# MB9AF31xK register map
Vendor: Cypress; File version: 2.1
CPU: CM3 r2p1, little endian, MPU, no FPU, 4 interrupt priority bits
Registers are 32-bit, read-write, reset 0x0 unless marked. A register's access mark holds for its fields unless they carry their own. Offsets are from the block's base; [hi:lo] are bit positions; 'fields as' and 'values as' point back to an identical list.

## MFS0 — Multi-function Serial Interface 0
Base 0x40038000
Same registers: MFS1 0x40038100
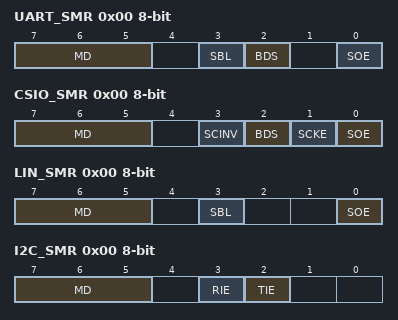
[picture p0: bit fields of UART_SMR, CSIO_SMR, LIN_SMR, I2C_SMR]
0x00 UART_SMR 8-bit (UART view) — Serial Mode Register [BHW]
  [7:5] MD — Operation mode set bit
  [3] SBL — Stop bit length select bit
  [2] BDS — Transfer direction select bit
  [0] SOE — Serial data output enable bit
0x00 CSIO_SMR 8-bit (CSIO view) — Serial Mode Register [BHW]
  [7:5] MD — Operation mode set bits
  [3] SCINV — Serial clock invert bit
  [2] BDS — Transfer direction select bit
  [1] SCKE — Master mode serial clock output enable bit
  [0] SOE — Serial data output enable bit
0x00 LIN_SMR 8-bit (LIN view) — Serial Mode Register [BHW]
  [7:5] MD — Operation mode setting bits
  [3] SBL — Stop bit length select bit
  [0] SOE — Serial data output enable bit
0x00 I2C_SMR 8-bit (I2C view) — Serial Mode Register [BHW]
  [7:5] MD — operation mode set bits
  [3] RIE — Received interrupt enable bit
  [2] TIE — Transmit interrupt enable bit
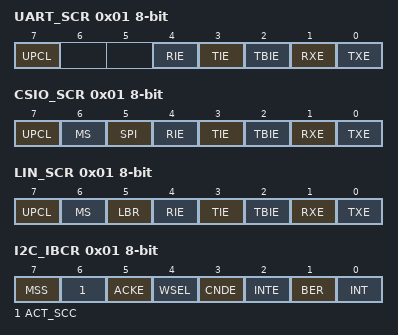
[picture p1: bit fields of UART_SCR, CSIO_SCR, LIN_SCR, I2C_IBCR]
0x01 UART_SCR 8-bit (UART view) — Serial Control Register [BHW]
  [7] UPCL — Programmable Clear bit
  [4] RIE — Received interrupt enable bit
  [3] TIE — Transmit interrupt enable bit
  [2] TBIE — Transmit bus idle interrupt enable bit
  [1] RXE — Received operation enable bit
  [0] TXE — Transmission operation enable bit
0x01 CSIO_SCR 8-bit (CSIO view) — Serial Control Register [BHW]
  [7] UPCL — Programmable clear bit
  [6] MS — Master/Slave function select bit
  [5] SPI — SPI corresponding bit
  [4] RIE — Received interrupt enable bit
  [3] TIE — Transmit interrupt enable bit
  [2] TBIE — Transmit bus idle interrupt enable bit
  [1] RXE — Data received enable bit
  [0] TXE — Data transmission enable bit
0x01 LIN_SCR 8-bit (LIN view) — Serial Control Register [BHW]
  [7] UPCL — Programmable clear bit
  [6] MS — Master/Slave function select bit
  [5] LBR — LIN Break Field setting bit (valid in master mode only)
  [4] RIE — Received interrupt enable bit
  [3] TIE — Transmit interrupt enable bit
  [2] TBIE — Transmit bus idle interrupt enable bit
  [1] RXE — Data reception enable bit
  [0] TXE — Data transmission enable bit
0x01 I2C_IBCR 8-bit (I2C view) — I2C Bus Control Register [BHW]
  [7] MSS — Master/slave select bit
  [6] ACT_SCC — Operation flag/iteration start condition generation bit
  [5] ACKE — Data byte acknowledge enable bit
  [4] WSEL — Wait selection bit
  [3] CNDE — Condition detection interrupt enable bit
  [2] INTE — Interrupt enable bit
  [1] BER ro — Bus error flag bit
  [0] INT — interrupt flag bit
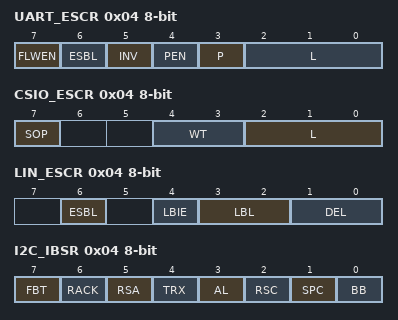
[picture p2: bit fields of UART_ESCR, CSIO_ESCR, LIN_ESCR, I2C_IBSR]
0x04 UART_ESCR 8-bit (UART view) — Extended Communication Control Register [BHW]
  [7] FLWEN — Flow control enable bit
  [6] ESBL — Extension stop bit length select bit
  [5] INV — Inverted serial data format bit
  [4] PEN — Parity enable bit (only functions in operation mode 0)
  [3] P — Parity select bit (only functions in operation mode 0)
  [2:0] L — Data length select bit
0x04 CSIO_ESCR 8-bit (CSIO view) — Extended Communication Control Register [BHW]
  [7] SOP — Serial output pin set bit
  [4:3] WT — Data transmit/received wait select bits
  [2:0] L — Data length select bits
0x04 LIN_ESCR 8-bit (LIN view) — Extended Communication Control Register [BHW]
  [6] ESBL — Extended stop bit length select bit
  [4] LBIE — LIN Break field detect interrupt enable bit
  [3:2] LBL — LIN Break field length select bits (valid in master mode only)
  [1:0] DEL — LIN Break delimiter length select bits (valid in master mode only)
0x04 I2C_IBSR 8-bit (I2C view) — I2C Bus Status Register [BHW]
  [7] FBT ro — First byte bit
  [6] RACK ro — Acknowledge flag bit
  [5] RSA ro — Reserved address detection bit
  [4] TRX ro — Data direction bit
  [3] AL ro — Arbitration lost bit
  [2] RSC — Iteration start condition check bit
  [1] SPC — Stop condition check bit
  [0] BB ro — Bus state bit
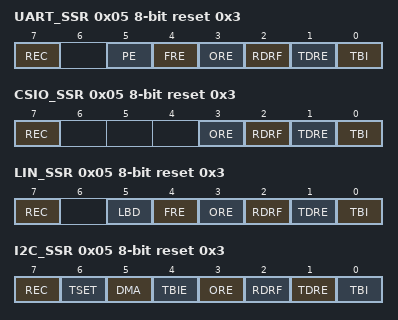
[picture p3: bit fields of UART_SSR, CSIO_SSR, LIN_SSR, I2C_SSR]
0x05 UART_SSR 8-bit reset 0x3 (UART view) — Serial Status Register [BHW]
  [7] REC — Received error flag clear bit
  [5] PE ro — Parity error flag bit (only functions in operation mode 0)
  [4] FRE ro — Framing error flag bit
  [3] ORE ro — Overrun error flag bit
  [2] RDRF ro — Received data full flag bit
  [1] TDRE ro — Transmit data empty flag bit
  [0] TBI ro — Transmit bus idle flag
0x05 CSIO_SSR 8-bit reset 0x3 (CSIO view) — Serial Status Register [BHW]
  [7] REC — Received error flag clear bit
  [3] ORE ro — Overrun error flag bit
  [2] RDRF ro — Received data full flag bit
  [1] TDRE ro — Transmit data empty flag bit
  [0] TBI ro — Transmit bus idle flag bit
0x05 LIN_SSR 8-bit reset 0x3 (LIN view) — Serial Status Register [BHW]
  [7] REC — Received Error flag clear bit
  [5] LBD — LIN Break field detection flag bit
  [4] FRE ro — Framing error flag bit
  [3] ORE ro — Overrun error flag bit
  [2] RDRF ro — Received data full flag bit
  [1] TDRE ro — Transmit data empty flag bit
  [0] TBI ro — Transmit bus idle flag bit
0x05 I2C_SSR 8-bit reset 0x3 (I2C view) — Serial Status Register [BHW]
  [7] REC — Received error flag clear bit
  [6] TSET — Transmit empty flag set bit
  [5] DMA — DMA mode enable bit
  [4] TBIE — Transmit bus idle interrupt enable bit (Effective only when DMA mode is enabled)
  [3] ORE ro — Overrun error flag bit
  [2] RDRF ro — Received data full flag bit
  [1] TDRE ro — Transmit data empty flag bit
  [0] TBI ro — Transmit bus idle flag bit (Effective only when DMA mode is enabled)
0x08 UART_RDR 16-bit ro (UART view) — Received Data Register [HW]
  [8:0] D — Data
0x08 UART_TDR 16-bit wo reset 0x1FF (UART view) — Transmit Data Register [HW]
  [8:0] D — Data
0x08 CSIO_RDR 16-bit ro (CSIO view) — Received Data Register [HW]
  [8:0] D — Data
0x08 CSIO_TDR 16-bit wo reset 0x1FF (CSIO view) — Transmit Data Register [HW]
  [8:0] D — Data
0x08 LIN_RDR 16-bit ro (LIN view) — Received Data Register [HW]
  [7:0] D — Data
0x08 LIN_TDR 16-bit wo reset 0xFF (LIN view) — Transmit Data Register [HW]
  [7:0] D — Data
0x08 I2C_RDR 16-bit ro (I2C view) — Received Data Register [HW]
  [7:0] D — Data
0x08 I2C_TDR 16-bit wo reset 0xFF (I2C view) — Transmit Data Register [HW]
  [7:0] D — Data
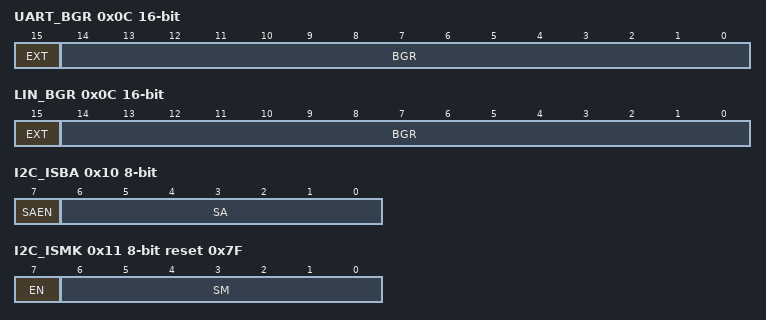
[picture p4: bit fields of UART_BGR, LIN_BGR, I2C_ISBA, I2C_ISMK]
0x0C UART_BGR 16-bit (UART view) — Baud Rate Generator Registers [BHW]
  [15] EXT — External clock select bit
  [14:0] BGR — Baud Rate Generator Registers 1
0x0C CSIO_BGR 16-bit (CSIO view) — Baud Rate Generator Registers [BHW]
  [14:0] BGR — Baud Rate Generator Registers 1
0x0C LIN_BGR 16-bit (LIN view) — Baud Rate Generator Registers [BHW]
  fields as UART_BGR
0x0C I2C_BGR 16-bit (I2C view) — Baud Rate Generator Registers [BHW]
  [14:0] BGR — Baud Rate Generator Registers 1
0x10 I2C_ISBA 8-bit (I2C view) — 7-bit Slave Address Register [BHW]
  [7] SAEN — Slave address enable bit
  [6:0] SA — 7-bit slave address
0x11 I2C_ISMK 8-bit reset 0x7F (I2C view) — 7-bit Slave Address Mask Register [BHW]
  [7] EN — I2C interface operation enable bit
  [6:0] SM — Slave address mask bits
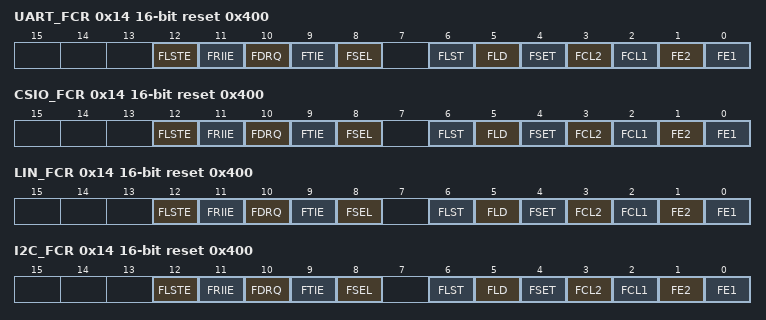
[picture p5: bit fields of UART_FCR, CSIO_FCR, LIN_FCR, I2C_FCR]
0x14 UART_FCR 16-bit reset 0x400 (UART view) — FIFO Control Register [BHW]
  [12] FLSTE — Re-transmission data lost detect enable bit
  [11] FRIIE — Received FIFO idle detection enable bit
  [10] FDRQ — Transmit FIFO data request bit
  [9] FTIE — Transmit FIFO interrupt enable bit
  [8] FSEL — FIFO select bit
  [6] FLST ro — FIFO re-transmit data lost flag bit
  [5] FLD — FIFO pointer reload bit
  [4] FSET — FIFO pointer save bit
  [3] FCL2 — FIFO2 reset bit
  [2] FCL1 — FIFO1 reset bit
  [1] FE2 — FIFO2 operation enable bit
  [0] FE1 — FIFO1 operation enable bit
0x14 CSIO_FCR 16-bit reset 0x400 (CSIO view) — FIFO Control Register [BHW]
  fields as UART_FCR
0x14 LIN_FCR 16-bit reset 0x400 (LIN view) — FIFO Control Register [BHW]
  fields as UART_FCR
0x14 I2C_FCR 16-bit reset 0x400 (I2C view) — FIFO Control Register [BHW]
  fields as UART_FCR
0x18 UART_FBYTE1 8-bit (UART view) — FIFO Byte Register 1 [BHW]
0x18 CSIO_FBYTE1 8-bit (CSIO view) — FIFO Byte Register 1 [BHW]
0x18 LIN_FBYTE1 8-bit (LIN view) — FIFO Byte Register 1 [BHW]
0x18 I2C_FBYTE1 8-bit (I2C view) — FIFO Byte Register 1 [BHW]
0x19 UART_FBYTE2 8-bit (UART view) — FIFO Byte Register 2 [BHW]
0x19 CSIO_FBYTE2 8-bit (CSIO view) — FIFO Byte Register 2 [BHW]
0x19 LIN_FBYTE2 8-bit (LIN view) — FIFO Byte Register 2 [BHW]
0x19 I2C_FBYTE2 8-bit (I2C view) — FIFO Byte Register 2 [BHW]

## MFS3 — Multi-function Serial Interface 3
Base 0x40038300
Registers as MFS0, without UART_FCR, CSIO_FCR, LIN_FCR, I2C_FCR, UART_FBYTE1, CSIO_FBYTE1, LIN_FBYTE1, I2C_FBYTE1, UART_FBYTE2, CSIO_FBYTE2, LIN_FBYTE2, I2C_FBYTE2.

## MFS5 — Multi-function Serial Interface 5
Base 0x40038500
Registers as MFS0, without CSIO_SMR, I2C_SMR, CSIO_SCR, I2C_IBCR, CSIO_ESCR, I2C_IBSR, CSIO_SSR, I2C_SSR, CSIO_RDR, CSIO_TDR, I2C_RDR, I2C_TDR, CSIO_BGR, I2C_BGR, I2C_ISBA, I2C_ISMK, UART_FCR, CSIO_FCR, LIN_FCR, I2C_FCR, UART_FBYTE1, CSIO_FBYTE1, LIN_FBYTE1, I2C_FBYTE1, UART_FBYTE2, CSIO_FBYTE2, LIN_FBYTE2, I2C_FBYTE2.
